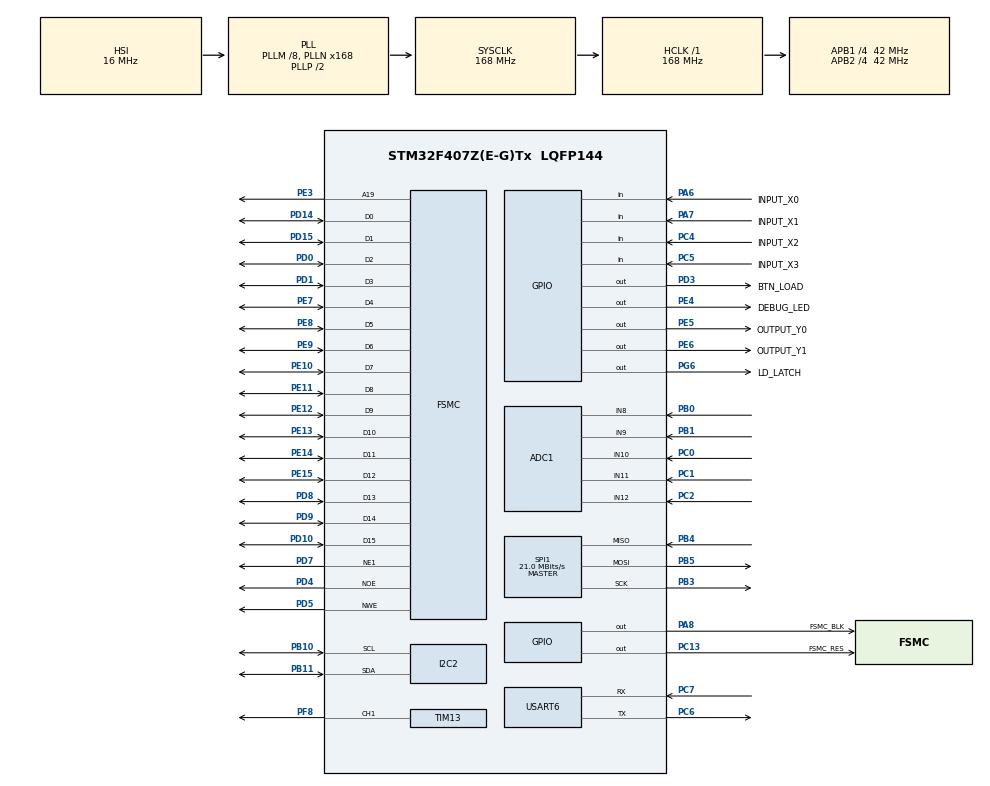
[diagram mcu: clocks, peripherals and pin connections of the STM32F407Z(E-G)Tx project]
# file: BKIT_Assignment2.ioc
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ADC1.Channel-0\#ChannelRegularConversion=ADC_CHANNEL_8
ADC1.Channel-1\#ChannelRegularConversion=ADC_CHANNEL_9
ADC1.Channel-2\#ChannelRegularConversion=ADC_CHANNEL_10
ADC1.Channel-3\#ChannelRegularConversion=ADC_CHANNEL_11
ADC1.Channel-4\#ChannelRegularConversion=ADC_CHANNEL_12
ADC1.NbrOfConversion=5
ADC1.NbrOfConversionFlag=1
ADC1.Rank-0\#ChannelRegularConversion=1
ADC1.Rank-1\#ChannelRegularConversion=2
ADC1.Rank-2\#ChannelRegularConversion=3
ADC1.Rank-3\#ChannelRegularConversion=4
ADC1.Rank-4\#ChannelRegularConversion=5
ADC1.SamplingTime-0\#ChannelRegularConversion=ADC_SAMPLETIME_15CYCLES
ADC1.SamplingTime-1\#ChannelRegularConversion=ADC_SAMPLETIME_15CYCLES
ADC1.SamplingTime-2\#ChannelRegularConversion=ADC_SAMPLETIME_15CYCLES
ADC1.SamplingTime-3\#ChannelRegularConversion=ADC_SAMPLETIME_15CYCLES
ADC1.SamplingTime-4\#ChannelRegularConversion=ADC_SAMPLETIME_15CYCLES
ADC1.ScanConvMode=ENABLE
ADC1.master=1
Dma.ADC1.0.Direction=DMA_PERIPH_TO_MEMORY
Dma.ADC1.0.FIFOMode=DMA_FIFOMODE_DISABLE
Dma.ADC1.0.Instance=DMA2_Stream0
Dma.ADC1.0.MemDataAlignment=DMA_MDATAALIGN_HALFWORD
Dma.ADC1.0.MemInc=DMA_MINC_ENABLE
Dma.ADC1.0.Mode=DMA_CIRCULAR
Dma.ADC1.0.PeriphDataAlignment=DMA_PDATAALIGN_HALFWORD
Dma.ADC1.0.PeriphInc=DMA_PINC_DISABLE
Dma.ADC1.0.Priority=DMA_PRIORITY_LOW
Dma.Request0=ADC1
FSMC.AddressSetupTime1=0xf
FSMC.BusTurnAroundDuration1=0
FSMC.DataSetupTime1=60
FSMC.ExtendedAddressSetupTime1=8
FSMC.ExtendedBusTurnAroundDuration1=0
FSMC.ExtendedDataSetupTime1=9
FSMC.ExtendedMode1=FSMC_EXTENDED_MODE_ENABLE
Mcu.Family=STM32F4
Mcu.Name=STM32F407Z(E-G)Tx
Mcu.Package=LQFP144
NVIC.DMA2_Stream0_IRQn=true\:0\:0\:false\:false\:true\:false\:true\:true
NVIC.PriorityGroup=NVIC_PRIORITYGROUP_4
NVIC.TIM2_IRQn=true\:0\:0\:false\:false\:true\:true\:true\:true
NVIC.TIM4_IRQn=true\:0\:0\:false\:false\:true\:true\:true\:true
NVIC.USART6_IRQn=true\:0\:0\:false\:false\:true\:true\:true\:true
PA13.Mode=Serial_Wire
PA13.Signal=SYS_JTMS-SWDIO
PA14.Mode=Serial_Wire
PA14.Signal=SYS_JTCK-SWCLK
PA6.GPIO_Label=INPUT_X0
PA6.Signal=GPIO_Input
PA7.GPIO_Label=INPUT_X1
PA7.Signal=GPIO_Input
PA8.GPIO_Label=FSMC_BLK
PA8.Signal=GPIO_Output
PB0.Signal=ADCx_IN8
PB1.Signal=ADCx_IN9
PB10.GPIO_Pu=GPIO_PULLUP
PB10.Mode=I2C
PB10.Signal=I2C2_SCL
PB11.GPIO_Pu=GPIO_PULLUP
PB11.Mode=I2C
PB11.Signal=I2C2_SDA
PB3.Mode=Full_Duplex_Master
PB3.Signal=SPI1_SCK
PB4.Mode=Full_Duplex_Master
PB4.Signal=SPI1_MISO
PB5.Mode=Full_Duplex_Master
PB5.Signal=SPI1_MOSI
PB6.Signal=I2C1_SCL
PB7.Signal=I2C1_SDA
PC0.Signal=ADCx_IN10
PC1.Signal=ADCx_IN11
PC13-ANTI_TAMP.GPIO_Label=FSMC_RES
PC13-ANTI_TAMP.Signal=GPIO_Output
PC2.Signal=ADCx_IN12
PC4.GPIO_Label=INPUT_X2
PC4.Signal=GPIO_Input
PC5.GPIO_Label=INPUT_X3
PC5.Signal=GPIO_Input
PC6.Mode=Asynchronous
PC6.Signal=USART6_TX
PC7.Mode=Asynchronous
PC7.Signal=USART6_RX
PD0.Signal=FSMC_D2_DA2
PD1.Signal=FSMC_D3_DA3
PD10.Signal=FSMC_D15_DA15
PD14.Signal=FSMC_D0_DA0
PD15.Signal=FSMC_D1_DA1
PD3.GPIO_Label=BTN_LOAD
PD3.Signal=GPIO_Output
PD4.Signal=FSMC_NOE
PD5.Signal=FSMC_NWE
PD7.Mode=NorPsramChipSelect1_1
PD7.Signal=FSMC_NE1
PD8.Signal=FSMC_D13_DA13
PD9.Signal=FSMC_D14_DA14
PE10.Signal=FSMC_D7_DA7
PE11.Signal=FSMC_D8_DA8
PE12.Signal=FSMC_D9_DA9
PE13.Signal=FSMC_D10_DA10
PE14.Signal=FSMC_D11_DA11
PE15.Signal=FSMC_D12_DA12
PE3.Signal=FSMC_A19
PE4.GPIO_Label=DEBUG_LED
PE4.Signal=GPIO_Output
PE5.GPIO_Label=OUTPUT_Y0
PE5.Signal=GPIO_Output
PE6.GPIO_Label=OUTPUT_Y1
PE6.Signal=GPIO_Output
PE7.Signal=FSMC_D4_DA4
PE8.Signal=FSMC_D5_DA5
PE9.Signal=FSMC_D6_DA6
PF8.Signal=S_TIM13_CH1
PG6.GPIO_Label=LD_LATCH
PG6.Signal=GPIO_Output
PH0-OSC_IN.Mode=HSE-External-Oscillator
PH0-OSC_IN.Signal=RCC_OSC_IN
PH1-OSC_OUT.Mode=HSE-External-Oscillator
PH1-OSC_OUT.Signal=RCC_OSC_OUT
ProjectManager.HeapSize=0x200
ProjectManager.StackSize=0x400
ProjectManager.TargetToolchain=STM32CubeIDE
RCC.48MHZClocksFreq_Value=84000000
RCC.AHBFreq_Value=168000000
RCC.APB1CLKDivider=RCC_HCLK_DIV4
RCC.APB1Freq_Value=42000000
RCC.APB1TimFreq_Value=84000000
RCC.APB2CLKDivider=RCC_HCLK_DIV4
RCC.APB2Freq_Value=42000000
RCC.APB2TimFreq_Value=84000000
RCC.CortexFreq_Value=168000000
RCC.HCLKFreq_Value=168000000
RCC.HSE_VALUE=8000000
RCC.HSI_VALUE=16000000
RCC.LSE_VALUE=32768
RCC.PLLM=8
RCC.PLLN=168
RCC.SYSCLKFreq_VALUE=168000000
RCC.SYSCLKSource=RCC_SYSCLKSOURCE_PLLCLK
RCC.VCOOutputFreq_Value=336000000
SH.ADCx_IN10.0=ADC1_IN10,IN10
SH.ADCx_IN11.0=ADC1_IN11,IN11
SH.ADCx_IN12.0=ADC1_IN12,IN12
SH.ADCx_IN8.0=ADC1_IN8,IN8
SH.ADCx_IN9.0=ADC1_IN9,IN9
SH.FSMC_A19.0=FSMC_A19,A19_1
SH.FSMC_D0_DA0.0=FSMC_D0,16b-d1
SH.FSMC_D10_DA10.0=FSMC_D10,16b-d1
SH.FSMC_D11_DA11.0=FSMC_D11,16b-d1
SH.FSMC_D12_DA12.0=FSMC_D12,16b-d1
SH.FSMC_D13_DA13.0=FSMC_D13,16b-d1
SH.FSMC_D14_DA14.0=FSMC_D14,16b-d1
SH.FSMC_D15_DA15.0=FSMC_D15,16b-d1
SH.FSMC_D1_DA1.0=FSMC_D1,16b-d1
SH.FSMC_D2_DA2.0=FSMC_D2,16b-d1
SH.FSMC_D3_DA3.0=FSMC_D3,16b-d1
SH.FSMC_D4_DA4.0=FSMC_D4,16b-d1
SH.FSMC_D5_DA5.0=FSMC_D5,16b-d1
SH.FSMC_D6_DA6.0=FSMC_D6,16b-d1
SH.FSMC_D7_DA7.0=FSMC_D7,16b-d1
SH.FSMC_D8_DA8.0=FSMC_D8,16b-d1
SH.FSMC_D9_DA9.0=FSMC_D9,16b-d1
SH.FSMC_NOE.0=FSMC_NOE,Lcd1
SH.FSMC_NWE.0=FSMC_NWE,Lcd1
SH.S_TIM13_CH1.0=TIM13_CH1,PWM Generation1 CH1
SPI1.CalculateBaudRate=21.0 MBits/s
SPI1.Direction=SPI_DIRECTION_2LINES
SPI1.Mode=SPI_MODE_MASTER
SPI1.VirtualType=VM_MASTER
TIM13.Channel=TIM_CHANNEL_1
TIM13.Period=100-1
TIM13.Prescaler=840-1
TIM2.Period=100-1
TIM2.Prescaler=840-1
TIM4.Period=100-1
TIM4.Prescaler=840-1
USART6.VirtualMode=VM_ASYNC
VP_TIM13_VS_ClockSourceINT.Mode=Enable_Timer
VP_TIM2_VS_ClockSourceINT.Mode=Internal
VP_TIM4_VS_ClockSourceINT.Mode=Internal
board=custom

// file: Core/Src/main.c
/* USER CODE BEGIN Header */
/**
  ******************************************************************************
  * @file           : main.c
  * @brief          : Main program body
  ******************************************************************************
  * @attention
  *
  * Copyright (c) 2026 STMicroelectronics.
  * All rights reserved.
  *
  * This software is licensed under terms that can be found in the LICENSE file
  * in the root directory of this software component.
  * If no LICENSE file comes with this software, it is provided AS-IS.
  *
  ******************************************************************************
  */
/* USER CODE END Header */
#include "main.h"
#include "adc.h"
#include "dma.h"
#include "i2c.h"
#include "spi.h"
#include "tim.h"
#include "usart.h"
#include "gpio.h"
#include "sensor.h"
#include "fsmc.h"
#include "bkit_app.h"
#include "application.h"
#include "software_timer.h"

void SystemClock_Config(void);
void system_init(void);

int main(void)
{

  /* MCU Configuration--------------------------------------------------------*/

  /* Reset of all peripherals, Initializes the Flash interface and the Systick. */
  HAL_Init();

  /* Configure the system clock */
  SystemClock_Config();

  /* Initialize all configured peripherals */
  MX_GPIO_Init();
  MX_DMA_Init();
  MX_TIM2_Init();
  MX_FSMC_Init();
  MX_TIM4_Init();
  MX_USART6_UART_Init();
  MX_ADC1_Init();
  MX_TIM13_Init();
  MX_SPI1_Init();
  MX_I2C2_Init();
  /* USER CODE BEGIN 2 */
  system_init();

  /* USER CODE END 2 */

  /* Infinite loop */
  while (1)
  {

    /* USER CODE BEGIN 3 */
	bkit_com_fsm();
  }
  /* USER CODE END 3 */
}

void SystemClock_Config(void)
{
  RCC_OscInitTypeDef RCC_OscInitStruct = {0};
  RCC_ClkInitTypeDef RCC_ClkInitStruct = {0};

  /** Configure the main internal regulator output voltage
  */
  __HAL_RCC_PWR_CLK_ENABLE();
  __HAL_PWR_VOLTAGESCALING_CONFIG(PWR_REGULATOR_VOLTAGE_SCALE1);

  /** Initializes the RCC Oscillators according to the specified parameters
  * in the RCC_OscInitTypeDef structure.
  */
  RCC_OscInitStruct.OscillatorType = RCC_OSCILLATORTYPE_HSI;
  RCC_OscInitStruct.HSIState = RCC_HSI_ON;
  RCC_OscInitStruct.HSICalibrationValue = RCC_HSICALIBRATION_DEFAULT;
  RCC_OscInitStruct.PLL.PLLState = RCC_PLL_ON;
  RCC_OscInitStruct.PLL.PLLSource = RCC_PLLSOURCE_HSI;
  RCC_OscInitStruct.PLL.PLLM = 8;
  RCC_OscInitStruct.PLL.PLLN = 168;
  RCC_OscInitStruct.PLL.PLLP = RCC_PLLP_DIV2;
  RCC_OscInitStruct.PLL.PLLQ = 4;
  if (HAL_RCC_OscConfig(&RCC_OscInitStruct) != HAL_OK)
  {
    Error_Handler();
  }

  /** Initializes the CPU, AHB and APB buses clocks
  */
  RCC_ClkInitStruct.ClockType = RCC_CLOCKTYPE_HCLK|RCC_CLOCKTYPE_SYSCLK
                              |RCC_CLOCKTYPE_PCLK1|RCC_CLOCKTYPE_PCLK2;
  RCC_ClkInitStruct.SYSCLKSource = RCC_SYSCLKSOURCE_PLLCLK;
  RCC_ClkInitStruct.AHBCLKDivider = RCC_SYSCLK_DIV1;
  RCC_ClkInitStruct.APB1CLKDivider = RCC_HCLK_DIV4;
  RCC_ClkInitStruct.APB2CLKDivider = RCC_HCLK_DIV4;

  if (HAL_RCC_ClockConfig(&RCC_ClkInitStruct, FLASH_LATENCY_5) != HAL_OK)
  {
    Error_Handler();
  }
}

/* USER CODE BEGIN 4 */
void system_init(void) {
	lcd_init();
	button_init();
	buzzer_init();
	sensor_init();
	timer_init();

}

void HAL_TIM_PeriodElapsedCallback(TIM_HandleTypeDef *htim)
{
  // Run software timers on TIM2 base period interrupt (1 ms)
  if (htim->Instance == TIM2)
  {
    timerRun();
  }
}

/* USER CODE END 4 */

void Error_Handler(void)
{
  __disable_irq();
  while (1)
  {
  }
}
